# SAM9X75D2G device description
Architecture: ARM926EJ-S; Family: SAM9; Series: SAM9X7
Registers are 32-bit, read-write, reset 0x0 unless marked. A register's access mark holds for its fields unless they carry their own. Offsets are from the block's base; [hi:lo] are bit positions; {n}, {i} and the like mark numbered series; 'fields as' and 'values as' point back to an identical list.

## MCAN — Controller Area Network
Instances: MCAN0 0xF8000000, MCAN1 0xF8004000
0x04 MCAN_ENDN ro reset 0x87654321 — Endian Register
  [31:0] ETV — Endianness Test Value
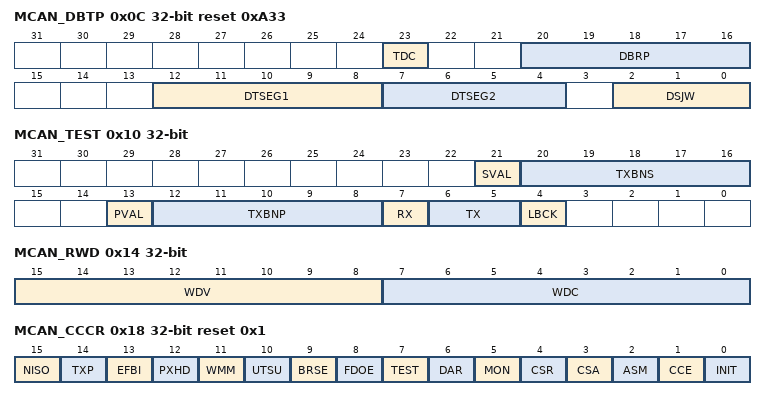
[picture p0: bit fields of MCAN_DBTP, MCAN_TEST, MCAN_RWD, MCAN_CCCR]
0x0C MCAN_DBTP reset 0xA33 — Data Bit Timing and Prescaler Register
  [23] TDC — Transmitter Delay Compensation
    0=DISABLED (Transmitter Delay Compensation disabled.); 1=ENABLED (Transmitter Delay Compensation enabled.)
  [20:16] DBRP — Data Bit Rate Prescaler
  [12:8] DTSEG1 — Data Time Segment Before Sample Point
    0=Forbidden
  [7:4] DTSEG2 — Data Time Segment After Sample Point
  [2:0] DSJW — Data (Re) Synchronization Jump Width
0x10 MCAN_TEST — Test Register
  [21] SVAL — Started Valid (read-only)
    0=DISABLED (TXBNS value is not valid.); 1=ENABLED (TXBNS value is valid.)
  [20:16] TXBNS — TX Buffer Number Started (read-only)
  [13] PVAL — Prepared Valid (read-only)
    0=DISABLED (TXBNP value is not valid.); 1=ENABLED (TXBNP value is valid.)
  [12:8] TXBNP — TX Buffer Number Prepared (read-only)
  [7] RX — Receive Pin (read-only)
    0=The CAN bus is dominant (CANRX = '0'); 1=The CAN bus is recessive (CANRX = '1')
  [6:5] TX — Control of Transmit Pin (read/write)
    0=RESET (Reset value, CANTX controlled by the CAN Core, updated at the end of the CAN bit time.); 1=SAMPLE_POINT_MONITORING (Sample Point can be monitored at pin CANTX.); 2=DOMINANT (Dominant ('0') level at pin CANTX.); 3=RECESSIVE (Recessive ('1') at pin CANTX.)
  [4] LBCK — Loop Back Mode (read/write)
    0=DISABLED (Reset value. Loop Back mode is disabled.); 1=ENABLED (Loop Back mode is enabled (see Section 6.1.9 "Test Modes").)
0x14 MCAN_RWD — RAM Watchdog Register
  [15:8] WDV — Watchdog Value (read-only)
  [7:0] WDC — Watchdog Configuration (read/write)
0x18 MCAN_CCCR reset 0x1 — CC Control Register
  [15] NISO — Non-ISO Operation
    0=CAN FD frame format according to ISO11898-1 (default); 1=CAN FD frame format according to Bosch CAN FD Specification V1.0
  [14] TXP — Transmit Pause (read/write, write protection)
    0=Transmit pause disabled; 1=Transmit pause enabled
  [13] EFBI — Edge Filtering during Bus Integration (read/write, write protection)
    0=Edge filtering is disabled; 1=Edge filtering is enabled. Two consecutive dominant tq required to detect an edge for hard synchronization.
  [12] PXHD — Protocol Exception Event Handling (read/write, write protection)
    0=Protocol exception handling enabled; 1=Protocol exception handling disabled
  [11] WMM — Wide Message Marker (read/write, write protection)
    0=DISABLED (8-bit message marker is used.); 1=ENABLED (16-bit message marker is used, replacing 16-bit timestamps in TX Event FIFO.)
  [10] UTSU — Use Timestamping Unit (read/write, write protection)
    0=DISABLED (Internal time stamping.); 1=ENABLED (External time stamping by TSU.)
  [9] BRSE — Bit Rate Switching Enable (read/write, write protection)
    0=DISABLED (Bit rate switching for transmissions disabled.); 1=ENABLED (Bit rate switching for transmissions enabled.)
  [8] FDOE — CAN FD Operation Enable (read/write, write protection)
    0=DISABLED (FD operation disabled.); 1=ENABLED (FD operation enabled.)
  [7] TEST — Test Mode Enable (read/write, write protection against '1')
    0=DISABLED (Normal operation, MCAN_TEST register holds reset values.); 1=ENABLED (Test mode, write access to MCAN_TEST register enabled.)
  [6] DAR — Disable Automatic Retransmission (read/write, write protection)
    0=AUTO_RETX (Automatic retransmission of messages not transmitted successfully enabled.); 1=NO_AUTO_RETX (Automatic retransmission disabled.)
  [5] MON — Bus Monitoring Mode (read/write, write protection against '1')
    0=DISABLED (Bus Monitoring mode is disabled.); 1=ENABLED (Bus Monitoring mode is enabled.)
  [4] CSR — Clock Stop Request (read/write)
    0=NO_CLOCK_STOP (No clock stop is requested.); 1=CLOCK_STOP (Clock stop requested. When clock stop is requested, first INIT and then CSA will be set after all pending transfer requests have been completed and the CAN bus reached idle.)
  [3] CSA — Clock Stop Acknowledge (read-only)
    0=No clock stop acknowledged; 1=MCAN may be set in power down by stopping the peripheral clock and the CAN core clock
  [2] ASM — Restricted Operation Mode (read/write, write protection against '1')
    0=NORMAL (Normal CAN operation.); 1=RESTRICTED (Restricted Operation mode active.)
  [1] CCE — Configuration Change Enable (read/write, write protection)
    0=PROTECTED (The processor has no write access to the protected configuration registers.); 1=CONFIGURABLE (The processor has write access to the protected configuration registers (while MCAN_CCCR.INIT = '1').)
  [0] INIT — Initialization (read/write)
    0=DISABLED (Normal operation.); 1=ENABLED (Initialization is started.)
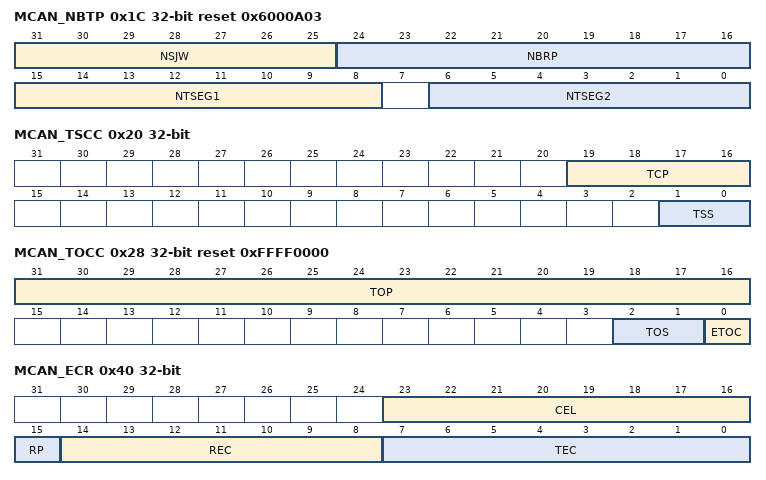
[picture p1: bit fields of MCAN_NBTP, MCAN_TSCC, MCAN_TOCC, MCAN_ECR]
0x1C MCAN_NBTP reset 0x6000A03 — Nominal Bit Timing and Prescaler Register
  [31:25] NSJW — Nominal (Re) Synchronization Jump Width
  [24:16] NBRP — Nominal Bit Rate Prescaler
  [15:8] NTSEG1 — Nominal Time Segment Before Sample Point
    0=Forbidden
  [6:0] NTSEG2 — Nominal Time Segment After Sample Point
0x20 MCAN_TSCC — Timestamp Counter Configuration Register
  [19:16] TCP — Timestamp Counter Prescaler
  [1:0] TSS — Timestamp Select
    0=ALWAYS_0 (Timestamp counter value always 0x0000); 1=TCP_INC (Timestamp counter value incremented according to TCP); 2=EXT_TIMESTAMP (External timestamp counter value used); 3=ALWAYS_0_a (Timestamp counter value always 0x0000)
0x24 MCAN_TSCV — Timestamp Counter Value Register
  [15:0] TSC — Timestamp Counter (cleared on write)
0x28 MCAN_TOCC reset 0xFFFF0000 — Timeout Counter Configuration Register
  [31:16] TOP — Timeout Period
  [2:1] TOS — Timeout Select
    0=CONTINUOUS (Continuous operation); 1=TX_EV_TIMEOUT (Timeout controlled by Tx Event FIFO); 2=RX0_EV_TIMEOUT (Timeout controlled by Receive FIFO 0); 3=RX1_EV_TIMEOUT (Timeout controlled by Receive FIFO 1)
  [0] ETOC — Enable Timeout Counter
    0=NO_TIMEOUT (Timeout Counter disabled.); 1=TOS_CONTROLLED (Timeout Counter enabled.)
0x2C MCAN_TOCV reset 0xFFFF — Timeout Counter Value Register
  [15:0] TOC — Timeout Counter (cleared on write)
0x40 MCAN_ECR ro — Error Counter Register
  [23:16] CEL — CAN Error Logging (cleared on read)
  [15] RP — Receive Error Passive
    0=The Receive Error Counter is below the error passive level of 128; 1=The Receive Error Counter has reached the error passive level of 128
  [14:8] REC — Receive Error Counter
  [7:0] TEC — Transmit Error Counter
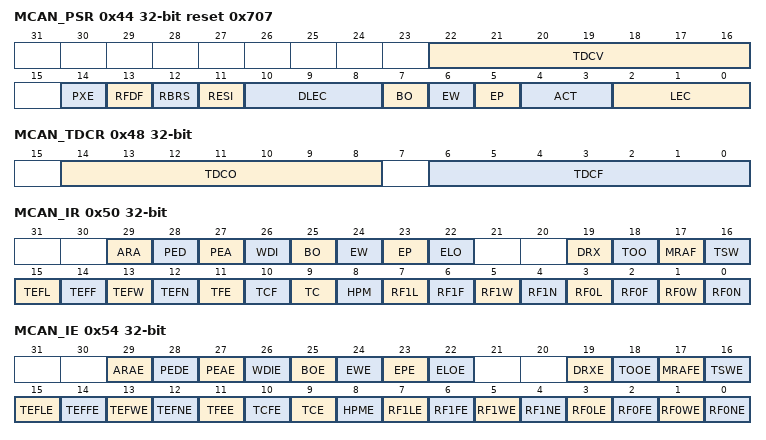
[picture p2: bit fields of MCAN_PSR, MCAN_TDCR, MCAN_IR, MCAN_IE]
0x44 MCAN_PSR ro reset 0x707 — Protocol Status Register
  [22:16] TDCV — Transmitter Delay Compensation Value
  [14] PXE — Protocol Exception Event (cleared on read)
    0=No protocol exception event occurred since last read access; 1=Protocol exception event occurred
  [13] RFDF — Received a CAN FD Message (cleared on read)
    0=Since this bit was reset by the CPU, no CAN FD message has been received; 1=Message in CAN FD format with FDF flag set has been received
  [12] RBRS — BRS Flag of Last Received CAN FD Message (cleared on read)
    0=Last received CAN FD message did not have its BRS flag set; 1=Last received CAN FD message had its BRS flag set
  [11] RESI — ESI Flag of Last Received CAN FD Message (cleared on read)
    0=Last received CAN FD message did not have its ESI flag set; 1=Last received CAN FD message had its ESI flag set
  [10:8] DLEC — Data Phase Last Error Code (set to 111 on read)
  [7] BO — Bus_Off Status
    0=The MCAN is not Bus_Off; 1=The MCAN is in Bus_Off state
  [6] EW — Warning Status
    0=Both error counters are below the Error_Warning limit of 96; 1=At least one of error counter has reached the Error_Warning limit of 96
  [5] EP — Error Passive
    0=The MCAN is in the Error_Active state. It normally takes part in bus communication and sends an active error flag when an error has been detected.; 1=The MCAN is in the Error_Passive state
  [4:3] ACT — Activity
    0=SYNCHRONIZING (Node is synchronizing on CAN communication); 1=IDLE (Node is neither receiver nor transmitter); 2=RECEIVER (Node is operating as receiver); 3=TRANSMITTER (Node is operating as transmitter)
  [2:0] LEC — Last Error Code (set to 111 on read)
    0=NO_ERROR (No error occurred since LEC has been reset by successful reception or transmission.); 1=STUFF_ERROR (More than 5 equal bits in a sequence have occurred in a part of a received message where this is not allowed.); 2=FORM_ERROR (A fixed format part of a received frame has the wrong format.); 3=ACK_ERROR (The message transmitted by the MCAN was not acknowledged by another node.); 4=BIT1_ERROR (During transmission of a message (with the exception of the arbitration field), the device tried to send a recessive level (bit of logical value '1'), but the monitored bus value was dominant.); 5=BIT0_ERROR (During transmission of a message (or acknowledge bit, or active error flag, or overload flag), the device tried to send a dominant level (data or identifier bit logical value '0'), but the monitored bus value was recessive. During Bus_Off recovery, this status is set each time a sequence of 11 recessive bits has been monitored. This enables the processor to monitor the proceeding of the Bus_Off recovery sequence (indicating the bus is not stuck at dominant or continuously disturbed).); 6=CRC_ERROR (The CRC check sum of a received message was incorrect. The CRC of an incoming message does not match the CRC calculated from the received data.); 7=NO_CHANGE (Any read access to the Protocol Status Register re-initializes the LEC to '7'. When the LEC shows value '7', no CAN bus event was detected since the last processor read access to the Protocol Status Register.)
0x48 MCAN_TDCR — Transmit Delay Compensation Register
  [14:8] TDCO — Transmitter Delay Compensation Offset
  [6:0] TDCF — Transmitter Delay Compensation Filter
0x50 MCAN_IR — Interrupt Register
  [29] ARA — Access to Reserved Address
    0=No access to reserved address occurred; 1=Access to reserved address occurred
  [28] PED — Protocol Error in Data Phase
    0=No protocol error in data phase; 1=Protocol error in data phase detected (MCAN_PSR.DLEC differs from 0 or 7)
  [27] PEA — Protocol Error in Arbitration Phase
    0=No protocol error in arbitration phase; 1=Protocol error in arbitration phase detected (MCAN_PSR.LEC differs from 0 or 7)
  [26] WDI — Watchdog Interrupt
    0=No Message RAM Watchdog event occurred; 1=Message RAM Watchdog event due to missing READY
  [25] BO — Bus_Off Status
    0=Bus_Off status unchanged; 1=Bus_Off status changed
  [24] EW — Warning Status
    0=Error_Warning status unchanged; 1=Error_Warning status changed
  [23] EP — Error Passive
    0=Error_Passive status unchanged; 1=Error_Passive status changed
  [22] ELO — Error Logging Overflow
    0=CAN Error Logging Counter did not overflow; 1=Overflow of CAN Error Logging Counter occurred
  [19] DRX — Message stored to Dedicated Receive Buffer
    0=No Receive Buffer updated; 1=At least one received message stored into a Receive Buffer
  [18] TOO — Timeout Occurred
    0=No timeout; 1=Timeout reached
  [17] MRAF — Message RAM Access Failure
    0=No Message RAM access failure occurred; 1=Message RAM access failure occurred
  [16] TSW — Timestamp Wraparound
    0=No timestamp counter wrap-around; 1=Timestamp counter wrapped around
  [15] TEFL — Tx Event FIFO Element Lost
    0=No Tx Event FIFO element lost; 1=Tx Event FIFO element lost, also set after write attempt to Tx Event FIFO of size zero
  [14] TEFF — Tx Event FIFO Full
    0=Tx Event FIFO not full; 1=Tx Event FIFO full
  [13] TEFW — Tx Event FIFO Watermark Reached
    0=Tx Event FIFO fill level below watermark; 1=Tx Event FIFO fill level reached watermark
  [12] TEFN — Tx Event FIFO New Entry
    0=Tx Event FIFO unchanged; 1=Tx Handler wrote Tx Event FIFO element
  [11] TFE — Tx FIFO Empty
    0=Tx FIFO non-empty; 1=Tx FIFO empty
  [10] TCF — Transmission Cancellation Finished
    0=No transmission cancellation finished; 1=Transmission cancellation finished
  [9] TC — Transmission Completed
    0=No transmission completed; 1=Transmission completed
  [8] HPM — High Priority Message
    0=No high priority message received; 1=High priority message received
  [7] RF1L — Receive FIFO 1 Message Lost
    0=No Receive FIFO 1 message lost; 1=Receive FIFO 1 message lost, also set after write attempt to Receive FIFO 1 of size zero
  [6] RF1F — Receive FIFO 1 Full
    0=Receive FIFO 1 not full; 1=Receive FIFO 1 full
  [5] RF1W — Receive FIFO 1 Watermark Reached
    0=Receive FIFO 1 fill level below watermark; 1=Receive FIFO 1 fill level reached watermark
  [4] RF1N — Receive FIFO 1 New Message
    0=No new message written to Receive FIFO 1; 1=New message written to Receive FIFO 1
  [3] RF0L — Receive FIFO 0 Message Lost
    0=No Receive FIFO 0 message lost; 1=Receive FIFO 0 message lost, also set after write attempt to Receive FIFO 0 of size zero
  [2] RF0F — Receive FIFO 0 Full
    0=Receive FIFO 0 not full; 1=Receive FIFO 0 full
  [1] RF0W — Receive FIFO 0 Watermark Reached
    0=Receive FIFO 0 fill level below watermark; 1=Receive FIFO 0 fill level reached watermark
  [0] RF0N — Receive FIFO 0 New Message
    0=No new message written to Receive FIFO 0; 1=New message written to Receive FIFO 0
0x54 MCAN_IE — Interrupt Enable Register
  [29] ARAE — Access to Reserved Address Enable
  [28] PEDE — Protocol Error in Data Phase Enable
  [27] PEAE — Protocol Error in Arbitration Phase Enable
  [26] WDIE — Watchdog Interrupt Enable
  [25] BOE — Bus_Off Status Interrupt Enable
  [24] EWE — Warning Status Interrupt Enable
  [23] EPE — Error Passive Interrupt Enable
  [22] ELOE — Error Logging Overflow Interrupt Enable
  [19] DRXE — Message stored to Dedicated Receive Buffer Interrupt Enable
  [18] TOOE — Timeout Occurred Interrupt Enable
  [17] MRAFE — Message RAM Access Failure Interrupt Enable
  [16] TSWE — Timestamp Wraparound Interrupt Enable
  [15] TEFLE — Tx Event FIFO Event Lost Interrupt Enable
  [14] TEFFE — Tx Event FIFO Full Interrupt Enable
  [13] TEFWE — Tx Event FIFO Watermark Reached Interrupt Enable
  [12] TEFNE — Tx Event FIFO New Entry Interrupt Enable
  [11] TFEE — Tx FIFO Empty Interrupt Enable
  [10] TCFE — Transmission Cancellation Finished Interrupt Enable
  [9] TCE — Transmission Completed Interrupt Enable
  [8] HPME — High Priority Message Interrupt Enable
  [7] RF1LE — Receive FIFO 1 Message Lost Interrupt Enable
  [6] RF1FE — Receive FIFO 1 Full Interrupt Enable
  [5] RF1WE — Receive FIFO 1 Watermark Reached Interrupt Enable
  [4] RF1NE — Receive FIFO 1 New Message Interrupt Enable
  [3] RF0LE — Receive FIFO 0 Message Lost Interrupt Enable
  [2] RF0FE — Receive FIFO 0 Full Interrupt Enable
  [1] RF0WE — Receive FIFO 0 Watermark Reached Interrupt Enable
  [0] RF0NE — Receive FIFO 0 New Message Interrupt Enable
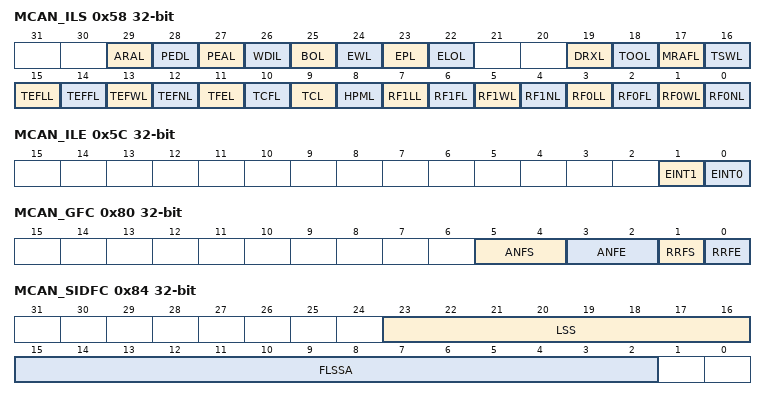
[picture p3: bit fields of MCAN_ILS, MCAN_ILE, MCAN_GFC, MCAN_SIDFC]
0x58 MCAN_ILS — Interrupt Line Select Register
  [29] ARAL — Access to Reserved Address Line
  [28] PEDL — Protocol Error in Data Phase Line
  [27] PEAL — Protocol Error in Arbitration Phase Line
  [26] WDIL — Watchdog Interrupt Line
  [25] BOL — Bus_Off Status Interrupt Line
  [24] EWL — Warning Status Interrupt Line
  [23] EPL — Error Passive Interrupt Line
  [22] ELOL — Error Logging Overflow Interrupt Line
  [19] DRXL — Message stored to Dedicated Receive Buffer Interrupt Line
  [18] TOOL — Timeout Occurred Interrupt Line
  [17] MRAFL — Message RAM Access Failure Interrupt Line
  [16] TSWL — Timestamp Wraparound Interrupt Line
  [15] TEFLL — Tx Event FIFO Event Lost Interrupt Line
  [14] TEFFL — Tx Event FIFO Full Interrupt Line
  [13] TEFWL — Tx Event FIFO Watermark Reached Interrupt Line
  [12] TEFNL — Tx Event FIFO New Entry Interrupt Line
  [11] TFEL — Tx FIFO Empty Interrupt Line
  [10] TCFL — Transmission Cancellation Finished Interrupt Line
  [9] TCL — Transmission Completed Interrupt Line
  [8] HPML — High Priority Message Interrupt Line
  [7] RF1LL — Receive FIFO 1 Message Lost Interrupt Line
  [6] RF1FL — Receive FIFO 1 Full Interrupt Line
  [5] RF1WL — Receive FIFO 1 Watermark Reached Interrupt Line
  [4] RF1NL — Receive FIFO 1 New Message Interrupt Line
  [3] RF0LL — Receive FIFO 0 Message Lost Interrupt Line
  [2] RF0FL — Receive FIFO 0 Full Interrupt Line
  [1] RF0WL — Receive FIFO 0 Watermark Reached Interrupt Line
  [0] RF0NL — Receive FIFO 0 New Message Interrupt Line
0x5C MCAN_ILE — Interrupt Line Enable Register
  [1] EINT1 — Enable Interrupt Line 1
    0=Interrupt line MCAN_INT1 disabled; 1=Interrupt line MCAN_INT1 enabled
  [0] EINT0 — Enable Interrupt Line 0
    0=Interrupt line MCAN_INT0 disabled; 1=Interrupt line MCAN_INT0 enabled
0x80 MCAN_GFC — Global Filter Configuration Register
  [5:4] ANFS — Accept Non-matching Frames Standard
    0=RX_FIFO_0 (Accept in Rx FIFO 0); 1=RX_FIFO_1 (Accept in Rx FIFO 1)
  [3:2] ANFE — Accept Non-matching Frames Extended
    values as ANFS
  [1] RRFS — Reject Remote Frames Standard
    0=FILTER (Filter remote frames with 11-bit standard IDs.); 1=REJECT (Reject all remote frames with 11-bit standard IDs.)
  [0] RRFE — Reject Remote Frames Extended
    0=FILTER (Filter remote frames with 29-bit extended IDs.); 1=REJECT (Reject all remote frames with 29-bit extended IDs.)
0x84 MCAN_SIDFC — Standard ID Filter Configuration Register
  [23:16] LSS — List Size Standard
    0=No standard Message ID filter
  [15:2] FLSSA — Filter List Standard Start Address
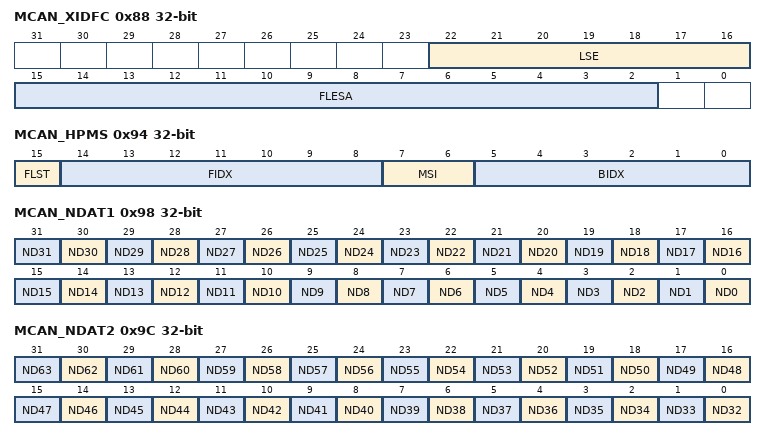
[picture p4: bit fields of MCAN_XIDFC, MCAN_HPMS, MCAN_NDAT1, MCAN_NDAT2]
0x88 MCAN_XIDFC — Extended ID Filter Configuration Register
  [22:16] LSE — List Size Extended
    0=No extended Message ID filter
  [15:2] FLESA — Filter List Extended Start Address
0x90 MCAN_XIDAM reset 0x1FFFFFFF — Extended ID AND Mask Register
  [28:0] EIDM — Extended ID Mask
0x94 MCAN_HPMS ro — High Priority Message Status Register
  [15] FLST — Filter List
    0=Standard filter list; 1=Extended filter list
  [14:8] FIDX — Filter Index
  [7:6] MSI — Message Storage Indicator
    0=NO_FIFO_SEL (No FIFO selected.); 1=LOST (FIFO message lost.); 2=FIFO_0 (Message stored in FIFO 0.); 3=FIFO_1 (Message stored in FIFO 1.)
  [5:0] BIDX — Buffer Index
0x98 MCAN_NDAT1 — New Data 1 Register
  [all] fields
    0=Receive Buffer not updated; 1=Receive Buffer updated from new message
  [n] ND{n} (n=0..31) — New Data
0x9C MCAN_NDAT2 — New Data 2 Register
  [all] fields
    values as the fields of MCAN_NDAT1
  [n-32] ND{n} (n=32..63) — New Data
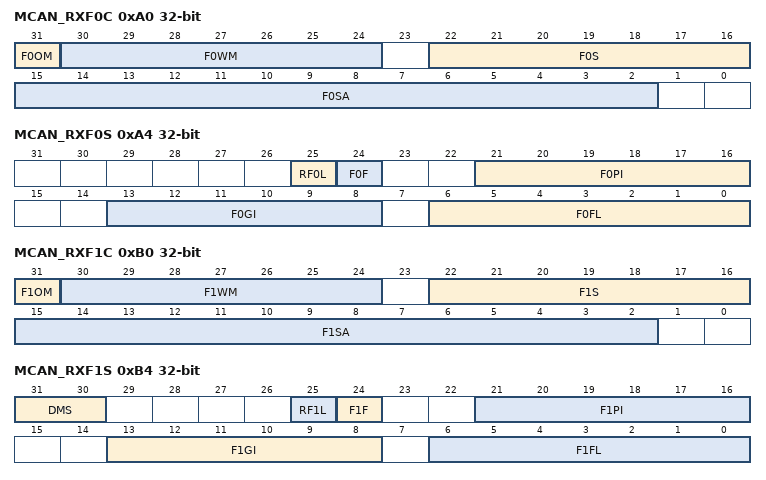
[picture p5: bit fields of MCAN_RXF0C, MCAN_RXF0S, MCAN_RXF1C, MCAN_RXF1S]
0xA0 MCAN_RXF0C — Receive FIFO 0 Configuration Register
  [31] F0OM — FIFO 0 Operation Mode
    0=FIFO 0 Blocking mode; 1=FIFO 0 Overwrite mode
  [30:24] F0WM — Receive FIFO 0 Watermark
    0=Watermark interrupt disabled
  [22:16] F0S — Receive FIFO 0 Size
    0=No Receive FIFO 0
  [15:2] F0SA — Receive FIFO 0 Start Address
0xA4 MCAN_RXF0S ro — Receive FIFO 0 Status Register
  [25] RF0L — Receive FIFO 0 Message Lost
    values as MCAN_IR.RF0L
  [24] F0F — Receive FIFO 0 Full
    0=Receive FIFO 0 not full; 1=Receive FIFO 0 full
  [21:16] F0PI — Receive FIFO 0 Put Index
  [13:8] F0GI — Receive FIFO 0 Get Index
  [6:0] F0FL — Receive FIFO 0 Fill Level
0xA8 MCAN_RXF0A — Receive FIFO 0 Acknowledge Register
  [5:0] F0AI — Receive FIFO 0 Acknowledge Index
0xAC MCAN_RXBC — Receive Rx Buffer Configuration Register
  [15:2] RBSA — Receive Buffer Start Address
0xB0 MCAN_RXF1C — Receive FIFO 1 Configuration Register
  [31] F1OM — FIFO 1 Operation Mode
    0=FIFO 1 Blocking mode; 1=FIFO 1 Overwrite mode
  [30:24] F1WM — Receive FIFO 1 Watermark
    0=Watermark interrupt disabled
  [22:16] F1S — Receive FIFO 1 Size
    0=No Receive FIFO 1
  [15:2] F1SA — Receive FIFO 1 Start Address
0xB4 MCAN_RXF1S ro — Receive FIFO 1 Status Register
  [31:30] DMS — Debug Message Status
    0=IDLE (Idle state, wait for reception of debug messages, DMA request is cleared.); 1=MSG_A (Debug message A received.); 2=MSG_AB (Debug messages A, B received.); 3=MSG_ABC (Debug messages A, B, C received, DMA request is set.)
  [25] RF1L — Receive FIFO 1 Message Lost
    values as MCAN_IR.RF1L
  [24] F1F — Receive FIFO 1 Full
    0=Receive FIFO 1 not full; 1=Receive FIFO 1 full
  [21:16] F1PI — Receive FIFO 1 Put Index
  [13:8] F1GI — Receive FIFO 1 Get Index
  [6:0] F1FL — Receive FIFO 1 Fill Level
0xB8 MCAN_RXF1A — Receive FIFO 1 Acknowledge Register
  [5:0] F1AI — Receive FIFO 1 Acknowledge Index
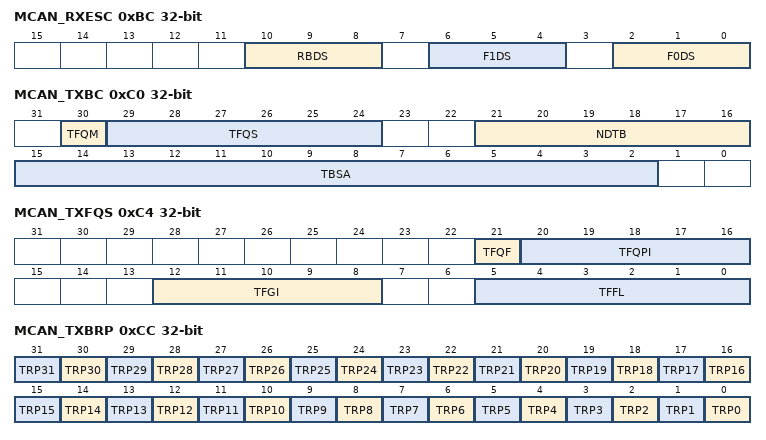
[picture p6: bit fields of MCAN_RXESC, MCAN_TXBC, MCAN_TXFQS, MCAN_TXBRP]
0xBC MCAN_RXESC — Receive Buffer / FIFO Element Size Configuration Register
  [all] fields
    0=8_BYTE (8-byte data field); 1=12_BYTE (12-byte data field); 2=16_BYTE (16-byte data field); 3=20_BYTE (20-byte data field); 4=24_BYTE (24-byte data field); 5=32_BYTE (32-byte data field); 6=48_BYTE (48-byte data field); 7=64_BYTE (64-byte data field)
  [10:8] RBDS — Receive Buffer Data Field Size
  [6:4] F1DS — Receive FIFO 1 Data Field Size
  [2:0] F0DS — Receive FIFO 0 Data Field Size
0xC0 MCAN_TXBC — Transmit Buffer Configuration Register
  [30] TFQM — Tx FIFO/Queue Mode
    0=Tx FIFO operation; 1=Tx Queue operation
  [29:24] TFQS — Transmit FIFO/Queue Size
    0=No Tx FIFO/Queue
  [21:16] NDTB — Number of Dedicated Transmit Buffers
    0=No dedicated Tx Buffers
  [15:2] TBSA — Tx Buffers Start Address
0xC4 MCAN_TXFQS ro — Transmit FIFO/Queue Status Register
  [21] TFQF — Tx FIFO/Queue Full
    0=Tx FIFO/Queue not full; 1=Tx FIFO/Queue full
  [20:16] TFQPI — Tx FIFO/Queue Put Index
  [12:8] TFGI — Tx FIFO Get Index
  [5:0] TFFL — Tx FIFO Free Level
0xC8 MCAN_TXESC — Transmit Buffer Element Size Configuration Register
  [2:0] TBDS — Tx Buffer Data Field Size
    0=8_BYTE (8-byte data field); 1=12_BYTE (12-byte data field); 2=16_BYTE (16-byte data field); 3=20_BYTE (20-byte data field); 4=24_BYTE (24-byte data field); 5=32_BYTE (32-byte data field); 6=48_BYTE (48- byte data field); 7=64_BYTE (64-byte data field)
0xCC MCAN_TXBRP ro — Transmit Buffer Request Pending Register
  [all] fields
    0=No transmission request pending; 1=Transmission request pending
  [n] TRP{n} (n=0..31) — Transmission Request Pending for Buffer {n}
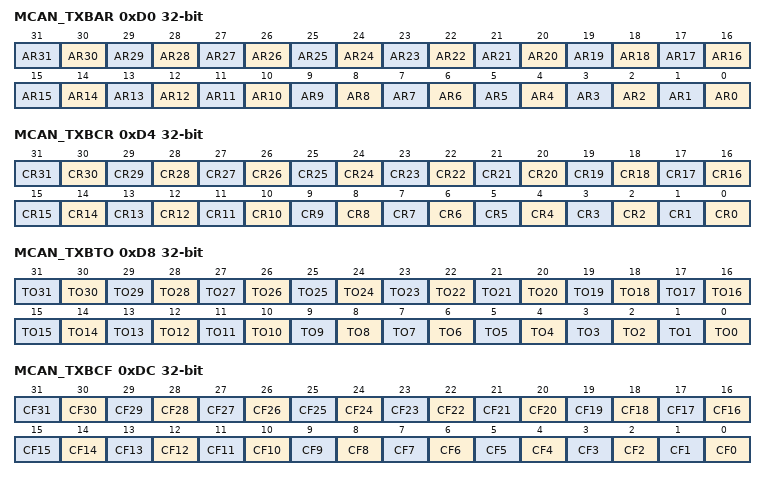
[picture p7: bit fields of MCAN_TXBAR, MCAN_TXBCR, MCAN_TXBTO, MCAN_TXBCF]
0xD0 MCAN_TXBAR — Transmit Buffer Add Request Register
  [all] fields
    0=No transmission request added; 1=Transmission requested added
  [n] AR{n} (n=0..31) — Add Request for Transmit Buffer {n}
0xD4 MCAN_TXBCR — Transmit Buffer Cancellation Request Register
  [all] fields
    0=No cancellation pending; 1=Cancellation pending
  [n] CR{n} (n=0..31) — Cancellation Request for Transmit Buffer {n}
0xD8 MCAN_TXBTO ro — Transmit Buffer Transmission Occurred Register
  [all] fields
    0=No transmission occurred; 1=Transmission occurred
  [n] TO{n} (n=0..31) — Transmission Occurred for Buffer {n}
0xDC MCAN_TXBCF ro — Transmit Buffer Cancellation Finished Register
  [all] fields
    0=No transmit buffer cancellation; 1=Transmit buffer cancellation finished
  [n] CF{n} (n=0..31) — Cancellation Finished for Transmit Buffer {n}
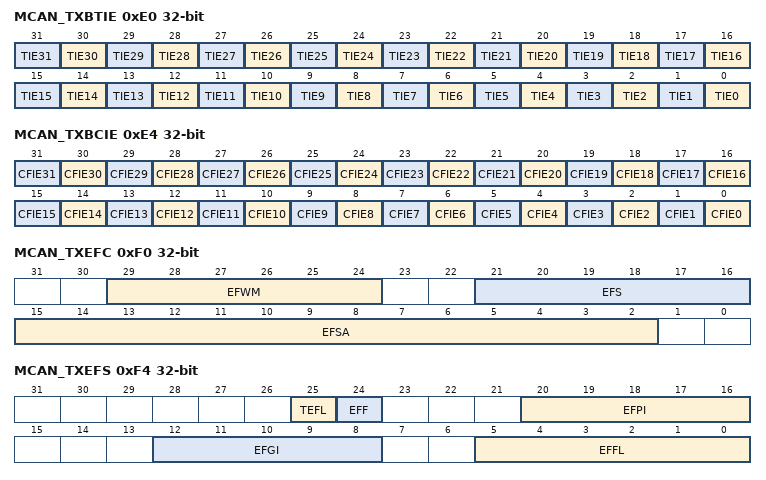
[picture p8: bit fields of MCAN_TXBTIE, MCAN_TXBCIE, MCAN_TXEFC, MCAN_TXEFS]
0xE0 MCAN_TXBTIE — Transmit Buffer Transmission Interrupt Enable Register
  [all] fields
    0=Transmission interrupt disabled; 1=Transmission interrupt enable
  [n] TIE{n} (n=0..31) — Transmission Interrupt Enable for Buffer {n}
0xE4 MCAN_TXBCIE — Transmit Buffer Cancellation Finished Interrupt Enable Register
  [all] fields
    0=Cancellation finished interrupt disabled; 1=Cancellation finished interrupt enabled
  [n] CFIE{n} (n=0..31) — Cancellation Finished Interrupt Enable for Transmit Buffer {n}
0xF0 MCAN_TXEFC — Transmit Event FIFO Configuration Register
  [29:24] EFWM — Event FIFO Watermark
    0=Watermark interrupt disabled
  [21:16] EFS — Event FIFO Size
    0=Tx Event FIFO disabled
  [15:2] EFSA — Event FIFO Start Address
0xF4 MCAN_TXEFS ro — Transmit Event FIFO Status Register
  [25] TEFL — Tx Event FIFO Element Lost
    values as MCAN_IR.TEFL
  [24] EFF — Event FIFO Full
    0=Tx Event FIFO not full; 1=Tx Event FIFO full
  [20:16] EFPI — Event FIFO Put Index
  [12:8] EFGI — Event FIFO Get Index
  [5:0] EFFL — Event FIFO Fill Level
0xF8 MCAN_TXEFA — Transmit Event FIFO Acknowledge Register
  [4:0] EFAI — Event FIFO Acknowledge Index
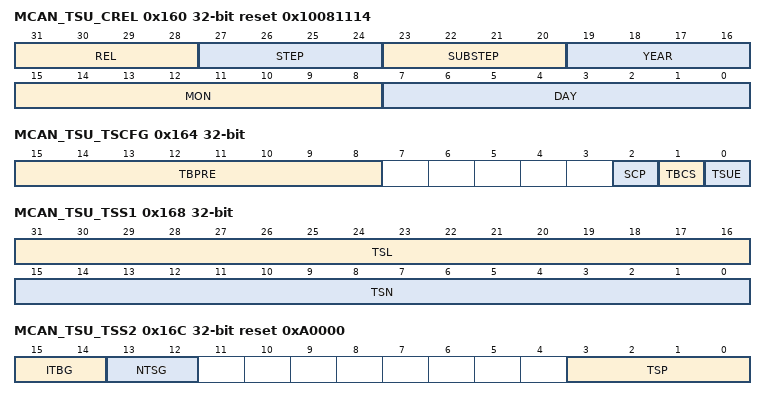
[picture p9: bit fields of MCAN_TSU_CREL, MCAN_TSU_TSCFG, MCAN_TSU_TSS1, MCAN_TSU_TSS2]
0x160 MCAN_TSU_CREL ro reset 0x10081114 — TSU Core Release Register
  [31:28] REL — Core Release
  [27:24] STEP — Core Release Step
  [23:20] SUBSTEP — Core Release Sub-step
  [19:16] YEAR — Timestamp Year
  [15:8] MON — Timestamp Month
  [7:0] DAY — Timestamp Day
0x164 MCAN_TSU_TSCFG — TSU Timestamp Configuration Register
  [15:8] TBPRE — Timebase Prescaler
  [2] SCP — Select Capturing Position
    0=Timestamp captured at EOF; 1=Timestamp captured at SOF
  [1] TBCS — Timebase Counter Select
    0=Timestamp value captured from internal timebase counter (32 bits); 1=Timestamp value captured from external timebase counter (32 bits)
  [0] TSUE — Timestamp Unit Enable
    0=TSU disabled; 1=TSU enabled
0x168 MCAN_TSU_TSS1 ro — TSU Timestamp Status 1 Register
  [31:16] TSL — Timestamp Lost
  [15:0] TSN — Timestamp New
0x16C MCAN_TSU_TSS2 ro reset 0xA0000 — TSU Timestamp Status 2 Register
  [15:14] ITBG — Internal Timebase and SOF Select Generic
  [13:12] NTSG — Number of Timestamps Generic
  [3:0] TSP — Timestamp Pointer
{0x170+4i} MCAN_TSU_TS[{i}] (i=0..15) ro — TSU Timestamp x Register
  [31:0] TS — Timestamp Word TS
0x1B0 MCAN_TSU_ATB ro — TSU Actual Timebase Register
  [31:0] TB — Timebase for Timestamp Generation
